# DMTIMER_1MS register map
Vendor: Texas Instruments
Peripheral module from a debugger description file (folder am335x).
Registers are 32-bit, read-write, no defined reset value unless marked. A register's access mark holds for its fields unless they carry their own. Offsets are as the file gives them; lines under a group give offsets from that group; [hi:lo] are bit positions; {n}, {i} and the like mark numbered series; 'fields as' and 'values as' point back to an identical list; <NAME> marks a mode.

## DMTIMER_1MS
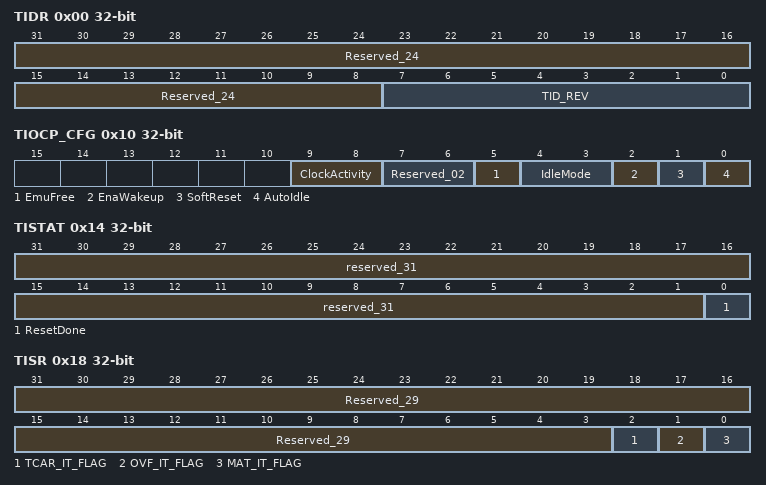
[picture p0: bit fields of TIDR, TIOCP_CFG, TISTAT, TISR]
0x00 TIDR ro — This register contains the IP revision code
  [31:8] Reserved_24 — Reads return 0
  [7:0] TID_REV — IP revision [7:4] Major revision [3:0] Minor revision Examples: 0x10 for 1.0, 0x21 for 2.1
0x10 TIOCP_CFG — This register controls the various parameters of the OCP interface
  [9:8] ClockActivity
    0=CA0 (Functional clock can be switched-off ; OCP clock can be switched-off); 1=CA1 (Functional clock can be switched-off ; OCP clock is maintained during wake-up period); 2=CA2 (Functional clock is maintained during wake-up period; OCP clock can be switched-off); 3=CA3 (Functional clock is maintained during wake-up period; OCP clock is maintained during wake-up period)
  [7:6] Reserved_02 — Write 0's for future compatibility Reads return 0
  [5] EmuFree — Emulation mode
    0=timer_frozen (Timer counter frozen in emulation); 1=timer_free (Timer counter free-running in emulation)
  [4:3] IdleMode — Power Management, req/ack control
    0=fidle (Force-idle. An idle request is acknowledged unconditionally); 1=nidle (No-idle. An idle request is never acknowledged); 2=sidle (Smart-idle. Acknowledgement to an idle request is given based on the internal activity of the module)
  [2] EnaWakeup — Wake-up feature global control
    0=No wakeup line assertion in idle mode; 1=enbwake (Wakeup line assertion enabled in smart-idle mode)
  [1] SoftReset — Software reset. This bit is automatically reset by the hardware. During reads, it always return 0
    0=nmode (Normal mode); 1=rstmode (The module is reset)
  [0] AutoIdle — Internal OCP clock gating strategy
    0=clkfree (OCP clock is free-running); 1=clkgate (Automatic OCP clock gating strategy is applied, based on the OCP interface activity)
0x14 TISTAT ro — This register provides status information about the module, excluding the interrupt status information
  [31:1] reserved_31 — Reads return 0 Reserved for OCP-socket status information
  [0] ResetDone — Internal reset monitoring
    0=rstongoing (Internal module reset in on-going); 1=rstcomp (Reset completed)
0x18 TISR access per field — The Timer Status Register is used to determine which of the timer events requested an interrupt.
  [31:3] Reserved_29 ro — Reads return 0
  [2] TCAR_IT_FLAG rw — indicates when an external pulse transition of the correct polarity is detected on the external pin PIEVENTCAPT
    0=no capture interrupt request; 1=TACR_IT_FLAG_1 (capture interrupt request)
  [1] OVF_IT_FLAG rw — TCRR overflow
    0=no overflow interrupt request; 1=overflow interrupt pending
  [0] MAT_IT_FLAG rw — the compare result of TCRR and TMAR
    0=no compare interrupt request; 1=compare interrupt pending
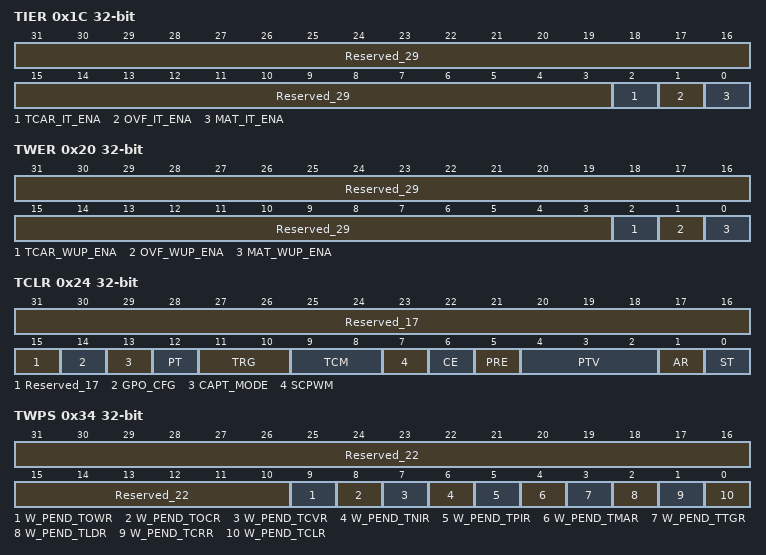
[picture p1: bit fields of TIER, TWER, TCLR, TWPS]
0x1C TIER access per field — This register controls (enable/disable) the interrupt events
  [31:3] Reserved_29 ro — Reads return 0
  [2] TCAR_IT_ENA rw — Enable capture interrupt
    0=Dsb_capt (Disable capture interrupt); 1=Enb_capt (Enable capture interrupt)
  [1] OVF_IT_ENA rw — Enable overflow interrupt
    0=Dsb_ovf (Disable overflow interrupt); 1=Enb_ovf (Enable overflow interrupt)
  [0] MAT_IT_ENA rw — Enable match interrupt
    0=Dsb_match (Disable match interrupt); 1=Enb_match (Enable match interrupt)
0x20 TWER access per field — This register controls (enable/disable) the wakeup feature on specific interrupt events
  [31:3] Reserved_29 ro — Reads return 0
  [2] TCAR_WUP_ENA rw — Enable capture wake-up
    0=DsbWupCap (Disable capture wake-up); 1=EnbWupCapt (Enable capture wake-up)
  [1] OVF_WUP_ENA rw — Enable overflow wake-up
    0=DsbWupOvf (Disable overflow wake-up); 1=EnbWupOvf (Enable overflow wake-up)
  [0] MAT_WUP_ENA rw — Enable match wake-up
    0=DsbWupMat (Disable match wake-up); 1=EnbWupMat (Enable match wake-up)
0x24 TCLR access per field — This register controls optional features specific to the timer functionality
  [31:15] Reserved_17 ro — Reads return 0
  [14] GPO_CFG rw
    0=PORGPOCFG drives 0; 1=PORGPOCFG drives 1
  [13] CAPT_MODE rw — Capture mode select bit (first/second)
    0=First_capt (Capture the first enabled capture event in TCAR1); 1=Sec_capt (Capture the second enabled capture event in TCAR2)
  [12] PT rw — Pulse or Toggle select bit
    0=pulse modulation; 1=toggle modulation
  [11:10] TRG rw — Trigger Output Mode
    0=no_trg (No trigger); 1=ovf_trg (Overflow trigger); 2=ovf_mat_trg (Overflow and match trigger)
  [9:8] TCM rw — Transition Capture Mode
    0=no_edge (No capture); 1=rise_edge (Capture on rising edges of PIEVETCAPT); 2=fall_edge (Capture on falling edges of PIEVETCAPT); 3=booth_edges (Capture on booth edges of PIEVETCAPT)
  [7] SCPWM rw — Pulse Width Modulation output pin default value
    0=def_low (default value of PORPWM: 0); 1=def_high (default value of PORPWM: 1)
  [6] CE rw — Compare enable
    0=dsb_cmp (Compare disabled); 1=enb_cmp (Compare enabled)
  [5] PRE rw — Prescaler enable
    0=no_prescal (Prescaler disabled); 1=prescal_on (Prescaler enabled)
  [4:2] PTV rw — Trigger Output Mode
    0=ptv (The timer counter is prescaled with the value: 2PTV. Example: PTV = 3: counter increases value is started after 8 functional clock periods)
  [1] AR rw — Auto-reload mode
    0=One shot mode overflow; 1=Auto-reload mode overflow
  [0] ST rw — Start/Stop timer control
    0=cnt_stop (Stop the timer); 1=cnt_start (Start the timer)
0x28 TCRR — This register holds the value of the internal counter
  [31:0] TIMER_COUNTER — The value of the timer counter register
0x2C TLDR — This register holds the timer's load value
  [31:0] LOAD_VALUE — The value of the timer load register
0x30 TTGR — This register triggers a counter reload of timer by writing any value in it.
  [31:0] TTGR_VALUE — The value of the trigger register During reads, it always returns "0xFFFFFFFF"
0x34 TWPS ro — This register contains the write posting bits for all writ-able functional registers
  [31:10] Reserved_22 — Reads return 0
  [9] W_PEND_TOWR — Write pending for register TOWR
    0=OWR_nPend (No Overflow Wrapping Register write pending.); 1=OWR_Pend (Overflow Wrapping Register write pending.)
  [8] W_PEND_TOCR — Write pending for register TOCR
    0=OCR_nPend (No Overflow Counter Register write pending.); 1=OCR_Pend (Overflow Counter Register write pending.)
  [7] W_PEND_TCVR — Write pending for register TCVR
    0=CVR_nPend (No Counter Register write pending.); 1=CVR_Pend (Counter Register write pending.)
  [6] W_PEND_TNIR — Write pending for register TNIR
    0=NIR_nPend (No Negativ Increment Register write pending.); 1=NIR_Pend (Negativ Increment Register write pending.)
  [5] W_PEND_TPIR — Write pending for register TPIR
    0=PIR_nPend (No Positive Increment Register write pending.); 1=PIR_Pend (Positive Increment Register write pending.)
  [4] W_PEND_TMAR — Write pending for register TMAR
    0=MAR_nPend (No Match Register write pending); 1=MAR_Pend (Match Register write pending)
  [3] W_PEND_TTGR — Write pending for register TTGR
    0=TGR_nPend (No Trigger Register write pending); 1=TGR_Pend (Trigger Register write pending)
  [2] W_PEND_TLDR — Write pending for register TLDR
    0=LDR_nPend (No Load Register write pending); 1=LDR_Pend (Load Register write pending)
  [1] W_PEND_TCRR — Write pending for register TCRR
    0=CRR_nPend (No Counter Register write pending); 1=CRR_Pend (Counter Register write pending)
  [0] W_PEND_TCLR — Write pending for register TCLR
    0=CLR_nPend (No Control Register write pending); 1=CLR_Pend (Control Register write pending)
0x38 TMAR — This register holds the match value to be compared with the counter's value
  [31:0] COMPARE_VALUE — The value of the match register
0x3C TCAR1 ro — This register holds the value of the first counter register capture
  [31:0] CAPTURE_VALUE1 — The value of first captured counter register
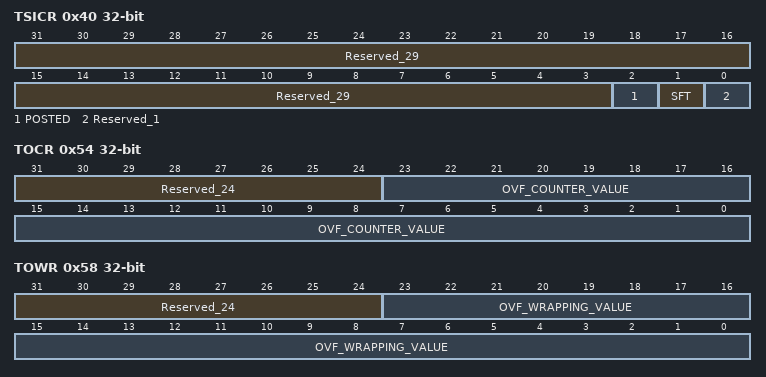
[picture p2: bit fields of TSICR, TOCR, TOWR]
0x40 TSICR access per field — Timer Synchronous Interface Control Register
  [31:3] Reserved_29 ro — Reads return 0
  [2] POSTED rw — posted mode active/inactive
    0=posted mode inactive: will delay the command accept output signal; 1=posted mode active (clocks ratio needs to fit freq (timer) < freq (OCP)/4 frequency requirement)
  [1] SFT rw — This bit reset all the functional part of the module
    0=software reset is disabled; 1=software reset is enabled
  [0] Reserved_1 ro — Reads return 0
0x44 TCAR2 ro — This register holds the value of the second counter register capture
  [31:0] CAPTURE_VALUE2 — The value of second captured counter register
0x48 TPIR — This register is used for 1ms tick generation. The TPIR register holds the value of the positive increment. The value of this register is added with the value of the TCVR to define whether next value loaded in TCRR will be the sub-period value or the over-period value.
  [31:0] POSITIVE_INC_VALUE — The value of the positive increment.
0x4C TNIR — This register is used for 1ms tick generation. The TNIR register holds the value of the negative increment. The value of this register is added with the value of the TCVR to define whether next value loaded in TCRR will be the sub-period value or the over-period value.
  [31:0] NEGATIVE_INV_VALUE — The value of the negative increment.
0x50 TCVR — This register is used for 1ms tick generation. The TCVR register defines whether next value loaded in TCRR will be the sub-period value or the over-period value.
  [31:0] COUNTER_VALUE — The value of CVR counter.
0x54 TOCR access per field — This register is used to mask the tick interrupt for a selected number of ticks.
  [31:24] Reserved_24 ro — Reads return 0.
  [23:0] OVF_COUNTER_VALUE rw — The number of overflow events.
0x58 TOWR access per field — This register holds the number of masked overflow interrupts.
  [31:24] Reserved_24 ro — Reads return 0
  [23:0] OVF_WRAPPING_VALUE rw — The number of masked interrupts.
